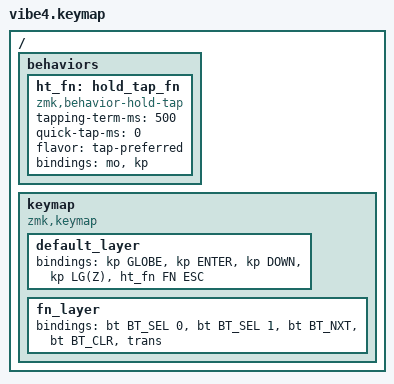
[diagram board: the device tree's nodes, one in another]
#include <behaviors.dtsi>
#include <dt-bindings/zmk/keys.h>
#include <dt-bindings/zmk/bt.h>

#define BASE 0
#define FN   1

/ {
	behaviors {
		/* K5: tap = Esc, hold(>=500ms) = momentary FN layer */
		ht_fn: hold_tap_fn {
			compatible = "zmk,behavior-hold-tap";
			#binding-cells = <2>;
			tapping-term-ms = <500>;
			quick-tap-ms = <0>;
			flavor = "tap-preferred";
			bindings = <&mo>, <&kp>;
		};
	};

	keymap {
		compatible = "zmk,keymap";

		default_layer {
			bindings = <
				&kp GLOBE   &kp ENTER   &kp DOWN   &kp LG(Z)   &ht_fn FN ESC
			>;
		};

		fn_layer {
			bindings = <
				&bt BT_SEL 0   &bt BT_SEL 1   &bt BT_NXT   &bt BT_CLR   &trans
			>;
		};
	};
};
